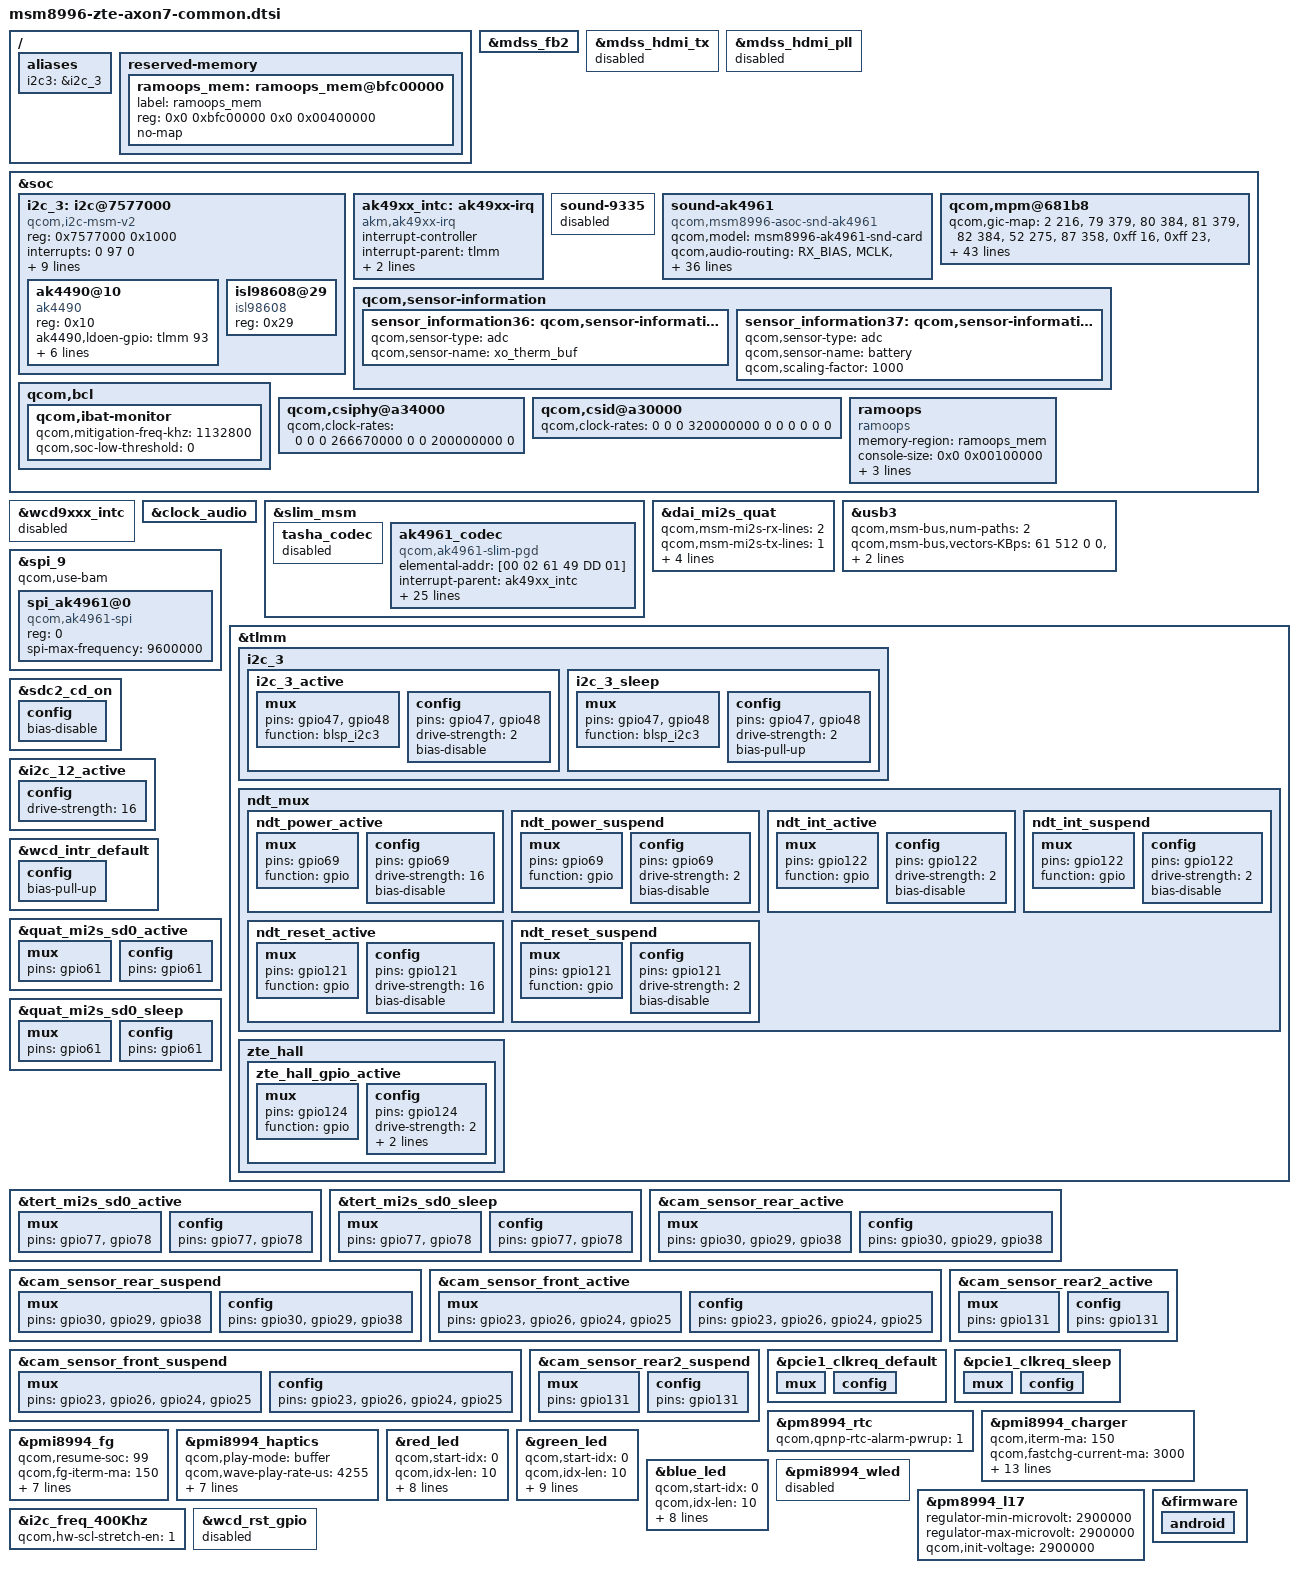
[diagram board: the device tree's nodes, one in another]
/* Copyright (c) 2015-2016, The Linux Foundation. All rights reserved.
 * Copyright (C) 2016 ZTE Corporation.
 *
 * This program is free software; you can redistribute it and/or modify
 * it under the terms of the GNU General Public License version 2 and
 * only version 2 as published by the Free Software Foundation.
 *
 * This program is distributed in the hope that it will be useful,
 * but WITHOUT ANY WARRANTY; without even the implied warranty of
 * MERCHANTABILITY or FITNESS FOR A PARTICULAR PURPOSE.  See the
 * GNU General Public License for more details.
 */

/*
 * ZTE Axon 7 (ailsa_ii): ZTE's changes to the shared msm8996 SoC and PMIC
 * dtsi files.
 *
 * ZTE's 3.18 kernel edited msm8996.dtsi, msm8996-pinctrl.dtsi,
 * msm-pmi8994.dtsi, msm-pm8994.dtsi, msm8996-regulator.dtsi,
 * msm8996-camera.dtsi, msm8996-blsp.dtsi and msm8996-pm.dtsi directly.
 * Here those changes are applied as overrides, so the shared 4.4 files stay
 * untouched. Each section names the file it overrides. Nodes for parts that
 * have no driver in this tree yet (AK4961 codec, AK4490 DAC, AK8157,
 * ISL98608) are kept so the board description is complete; they do not
 * probe until the drivers are ported.
 */

/* ---- msm8996.dtsi ---- */

/ {
	aliases {
		i2c3 = &i2c_3;
	};

	reserved-memory {
		/*
		 * No HDMI on this board. ZTE shrank this region to 0 bytes;
		 * drop it instead and free the 36 MB.
		 */
		/delete-node/ cont_splash_mem_hdmi@bdd00000;

		/*
		 * Where ZTE's 3.18 kernel (TWRP) and mainline (postmarketOS)
		 * keep ramoops, with their layout: the next boot of any of the
		 * three can read the log (dmesg zones, console, ftrace, pmsg).
		 */
		ramoops_mem: ramoops_mem@bfc00000 {
			label = "ramoops_mem";
			reg = <0x0 0xbfc00000 0x0 0x00400000>;
			no-map;
		};
	};
};

&mdss_fb2 {
	/delete-node/ qcom,cont-splash-memory;
};

&mdss_hdmi_tx {
	status = "disabled";
};

&mdss_hdmi_pll {
	status = "disabled";
};

&soc {
	i2c_3: i2c@7577000 { /* BLSP1 QUP3 */
		compatible = "qcom,i2c-msm-v2";
		#address-cells = <1>;
		#size-cells = <0>;
		reg = <0x7577000 0x1000>;
		reg-names = "qup_phys_addr";
		interrupt-names = "qup_irq";
		interrupts = <0 97 0>;
		dmas = <&dma_blsp1 16 64 0x20000020 0x20>,
			<&dma_blsp1 17 32 0x20000020 0x20>;
		dma-names = "tx", "rx";
		qcom,master-id = <86>;
		qcom,clk-freq-out = <400000>;
		qcom,clk-freq-in = <19200000>;
		clock-names = "iface_clk", "core_clk";
		clocks = <&clock_gcc clk_gcc_blsp1_ahb_clk>,
			<&clock_gcc clk_gcc_blsp1_qup3_i2c_apps_clk>;
		pinctrl-names = "i2c_active", "i2c_sleep";
		pinctrl-0 = <&i2c_3_active>;
		pinctrl-1 = <&i2c_3_sleep>;

		/* AKM AK4490 Hi-Fi DAC (no driver in this tree yet) */
		ak4490@10 {
			compatible = "ak4490";
			reg = <0x10>;
			ak4490,ldoen-gpio = <&tlmm 93 0>;
			ak4490,pdn-gpio = <&pmi8994_gpios 1 0>;
			qcom,isl-sw-pwr-gpio = <&pmi8994_gpios 10 0>;
			ak4490,isl-ldo-pwr-gpio = <&pmi8994_mpps 4 0>;
			ak4490,hifi_sel_gpio = <&pm8994_mpps 2 0>;
			ak4490,hifi_mute_gpio = <&pm8994_mpps 4 0>;
			ak4490,hifi_pop_gpio = <&tlmm 74 0>;
		};

		/* Intersil ISL98608 DAC power supply (no driver yet) */
		isl98608@29 {
			compatible = "isl98608";
			reg = <0x29>;
		};
	};

	/*
	 * The WCD9335 is not fitted: the slimbus codec is an AKM AK4961.
	 * Its interrupt line (gpio 54) goes to the AK49xx irq controller.
	 */
	ak49xx_intc: ak49xx-irq {
		compatible = "akm,ak49xx-irq";
		interrupt-controller;
		#interrupt-cells = <1>;
		interrupt-parent = <&tlmm>;
		qcom,gpio-connect = <&tlmm 54 0>;
		pinctrl-names = "default";
		pinctrl-0 = <&wcd_intr_default>;
	};

	sound-9335 {
		status = "disabled";
	};

	/* AK4961 machine driver (sound/soc/msm/msm8996-ak496x.c) */
	sound-ak4961 {
		compatible = "qcom,msm8996-asoc-snd-ak4961";
		qcom,model = "msm8996-ak4961-snd-card";
		qcom,audio-routing =
			"RX_BIAS", "MCLK",
			"AK4490_RX_BIAS", "MCLK";
		qcom,rcv-sw-gpio = <&pm8994_gpios 13 0>;
		qcom,ak4961-mclk-clk-freq = <9600000>;
		asoc-platform = <&pcm0>, <&pcm1>, <&pcm2>, <&voip>, <&voice>,
				<&loopback>, <&compress>, <&hostless>,
				<&afe>, <&lsm>, <&routing>, <&cpe>, <&compr>,
				<&pcmnoirq>;
		asoc-platform-names = "msm-pcm-dsp.0", "msm-pcm-dsp.1",
				"msm-pcm-dsp.2", "msm-voip-dsp",
				"msm-pcm-voice", "msm-pcm-loopback",
				"msm-compress-dsp", "msm-pcm-hostless",
				"msm-pcm-afe", "msm-lsm-client",
				"msm-pcm-routing", "msm-cpe-lsm",
				"msm-compr-dsp", "msm-pcm-dsp-noirq";
		asoc-cpu = <&dai_pri_auxpcm>, <&dai_sec_auxpcm>, <&dai_hdmi>,
				<&dai_mi2s>, <&dai_mi2s_quat>,
				<&sb_0_rx>, <&sb_0_tx>, <&sb_1_rx>, <&sb_1_tx>,
				<&sb_2_rx>, <&sb_2_tx>, <&sb_3_rx>, <&sb_3_tx>,
				<&sb_4_rx>, <&sb_4_tx>, <&sb_5_tx>,
				<&afe_pcm_rx>, <&afe_pcm_tx>,
				<&afe_proxy_rx>, <&afe_proxy_tx>,
				<&incall_record_rx>, <&incall_record_tx>,
				<&incall_music_rx>, <&incall_music2_rx>,
				<&sb_5_rx>;
		asoc-cpu-names = "msm-dai-q6-auxpcm.1", "msm-dai-q6-auxpcm.2",
				"msm-dai-q6-hdmi.8", "msm-dai-q6-mi2s.2",
				"msm-dai-q6-mi2s.3",
				"msm-dai-q6-dev.16384", "msm-dai-q6-dev.16385",
				"msm-dai-q6-dev.16386", "msm-dai-q6-dev.16387",
				"msm-dai-q6-dev.16388", "msm-dai-q6-dev.16389",
				"msm-dai-q6-dev.16390", "msm-dai-q6-dev.16391",
				"msm-dai-q6-dev.16392", "msm-dai-q6-dev.16393",
				"msm-dai-q6-dev.16395", "msm-dai-q6-dev.224",
				"msm-dai-q6-dev.225", "msm-dai-q6-dev.241",
				"msm-dai-q6-dev.240", "msm-dai-q6-dev.32771",
				"msm-dai-q6-dev.32772", "msm-dai-q6-dev.32773",
				"msm-dai-q6-dev.32770", "msm-dai-q6-dev.16394";
		asoc-codec = <&stub_codec>;
		asoc-codec-names = "msm-stub-codec.1";
	};

	/* MPM wakeup map: ZTE adds blsp2_qup_irq(4) (gic 137) */
	qcom,mpm@681b8 {
		qcom,gic-map = <2 216>, /* tsens_upper_lower_int */
				<79 379>,   /* qusb2phy_dmse_hv_prim */
				<80 384>,   /* qusb2phy_dmse_hv_sec */
				<81 379>,   /* qusb2phy_dpse_hv_prim */
				<82 384>,   /* qusb2phy_dpse_hv_sec */
				<52 275>,   /* qmp_usb3_lfps_rxterm_irq */
				<87 358>,   /* ee0_krait_hlos_spmi_periph_irq */
				<0xff 16>,  /* APCj_qgicdrCpu0HwFaultIrptReq */
				<0xff 23>,  /* APCj_qgicdrCpu0PerfMonIrptReq */
				<0xff 27>,  /* APCj_qgicdrCpu0QTmrVirtIrptReq */
				<0xff 32>,  /* APCj_qgicdrL2PerfMonIrptReq */
				<0xff 33>,  /* APCC_qgicL2PerfMonIrptReq */
				<0xff 34>,  /* APCC_qgicL2ErrorIrptReq */
				<0xff 35>,  /* WDT_barkInt */
				<0xff 40>,  /* qtimer_phy_irq */
				<0xff 41>,  /* APCj_qgicdrL2HwFaultNonFatalIrptReq */
				<0xff 42>,  /* APCj_qgicdrL2HwFaultFatalIrptReq */
				<0xff 49>,  /* L3UX_qgicL3ErrorIrptReq */
				<0xff 54>,  /* M4M_sysErrorInterrupt */
				<0xff 55>,  /* M4M_sysDlmInterrupt */
				<0xff 57>,  /* mss_to_apps_irq(0) */
				<0xff 58>,  /* mss_to_apps_irq(1) */
				<0xff 59>,  /* mss_to_apps_irq(2) */
				<0xff 60>,  /* mss_to_apps_irq(3) */
				<0xff 61>,  /* mss_a2_bam_irq */
				<0xff 62>,  /* QTMR_qgicFrm0VirtIrq */
				<0xff 63>,  /* QTMR_qgicFrm1PhysIrq */
				<0xff 64>,  /* QTMR_qgicFrm2PhysIrq */
				<0xff 65>,  /* QTMR_qgicFrm3PhysIrq */
				<0xff 66>,  /* QTMR_qgicFrm4PhysIrq */
				<0xff 67>,  /* QTMR_qgicFrm5PhysIrq */
				<0xff 68>,  /* QTMR_qgicFrm6PhysIrq */
				<0xff 69>,  /* QTMR_qgicFrm7PhysIrq */
				<0xff 70>,  /* iommu_pmon_nonsecure_irq */
				<0xff 74>,  /* osmmu_CIrpt[1] */
				<0xff 75>,  /* osmmu_CIrpt[0] */
				<0xff 77>,  /* osmmu_CIrpt[0] */
				<0xff 78>,  /* osmmu_CIrpt[0] */
				<0xff 79>,  /* osmmu_CIrpt[0] */
				<0xff 80>,  /* CPR3_irq */
				<0xff 94>,  /* osmmu_CIrpt[0] */
				<0xff 97>,  /* iommu_nonsecure_irq */
				<0xff 99>,  /* msm_iommu_pmon_nonsecure_irq */
				<0xff 101>, /* camss_jpeg_mmu_cirpt */
				<0xff 102>, /* osmmu_CIrpt[1] */
				<0xff 105>, /* iommu_pmon_nonsecure_irq */
				<0xff 108>, /* osmmu_PMIrpt */
				<0xff 109>, /* ocmem_dm_nonsec_irq */
				<0xff 110>, /* csiphy_0_irq */
				<0xff 111>, /* csiphy_1_irq */
				<0xff 112>, /* csiphy_2_irq */
				<0xff 115>, /* mdss_irq */
				<0xff 126>, /* bam_irq[0] */
				<0xff 127>, /* blsp1_qup_irq(0) */
				<0xff 129>, /* blsp2_qup_irq(3) */
				<0xff 132>, /* blsp1_qup_irq(5) */
				<0xff 133>, /* blsp2_qup_irq(0) */
				<0xff 134>, /* blsp2_qup_irq(1) */
				<0xff 135>, /* blsp2_qup_irq(3) */
				<0xff 137>, /* ZTE: blsp2_qup_irq(4) */
				<0xff 138>, /* blsp2_qup_irq(5) */
				<0xff 140>, /* blsp1_uart_irq(1) */
				<0xff 146>, /* blsp2_uart_irq(1) */
				<0xff 155>, /* sdcc_irq[0] */
				<0xff 157>, /* sdc2_irq[0] */
				<0xff 163>, /* usb30_ee1_irq */
				<0xff 164>, /* usb30_bam_irq(0) */
				<0xff 165>, /* usb30_hs_phy_irq */
				<0xff 166>, /* sdc1_pwr_cmd_irq */
				<0xff 170>, /* sdcc_pwr_cmd_irq */
				<0xff 171>, /* usb20_hs_phy_irq */
				<0xff 172>, /* usb20_power_event_irq */
				<0xff 173>, /* sdc1_irq[0] */
				<0xff 174>, /* o_wcss_apss_smd_med */
				<0xff 175>, /* o_wcss_apss_smd_low */
				<0xff 176>, /* o_wcss_apss_smsm_irq */
				<0xff 177>, /* o_wcss_apss_wlan_data_xfer_done */
				<0xff 178>, /* o_wcss_apss_wlan_rx_data_avail */
				<0xff 179>, /* o_wcss_apss_asic_intr */
				<0xff 180>, /* pcie20_2_int_pls_err */
				<0xff 181>, /* wcnss watchdog */
				<0xff 188>, /* lpass_irq_out_apcs(0) */
				<0xff 189>, /* lpass_irq_out_apcs(1) */
				<0xff 190>, /* lpass_irq_out_apcs(2) */
				<0xff 191>, /* lpass_irq_out_apcs(3) */
				<0xff 192>, /* lpass_irq_out_apcs(4) */
				<0xff 193>, /* lpass_irq_out_apcs(5) */
				<0xff 194>, /* lpass_irq_out_apcs(6) */
				<0xff 195>, /* lpass_irq_out_apcs(7) */
				<0xff 196>, /* lpass_irq_out_apcs(8) */
				<0xff 197>, /* lpass_irq_out_apcs(9) */
				<0xff 198>, /* coresight-tmc-etr interrupt */
				<0xff 200>, /* rpm_ipc(4) */
				<0xff 201>, /* rpm_ipc(5) */
				<0xff 202>, /* rpm_ipc(6) */
				<0xff 203>, /* rpm_ipc(7) */
				<0xff 204>, /* rpm_ipc(24) */
				<0xff 205>, /* rpm_ipc(25) */
				<0xff 206>, /* rpm_ipc(26) */
				<0xff 207>, /* rpm_ipc(27) */
				<0xff 208>,
				<0xff 210>,
				<0xff 211>, /* usb_dwc3_otg */
				<0xff 212>, /* usb30_power_event_irq */
				<0xff 215>, /* o_bimc_intr(0) */
				<0xff 224>, /* spdm_realtime_irq[1] */
				<0xff 238>, /* crypto_bam_irq[0] */
				<0xff 240>, /* summary_irq_kpss */
				<0xff 253>, /* sdc2_pwr_cmd_irq */
				<0xff 258>, /* lpass_irq_out_apcs[21] */
				<0xff 268>, /* bam_irq[1] */
				<0xff 270>, /* bam_irq[0] */
				<0xff 271>, /* bam_irq[0] */
				<0xff 276>, /* wlan_pci */
				<0xff 283>, /* pcie20_0_int_pls_err */
				<0xff 284>, /* pcie20_0_int_aer_legacy */
				<0xff 286>, /* pcie20_0_int_pls_link_down */
				<0xff 290>, /* ufs_ice_nonsec_level_irq */
				<0xff 293>, /* pcie20_2_int_pls_link_down */
				<0xff 295>, /* camss_cpp_mmu_cirpt[0] */
				<0xff 296>, /* camss_cpp_mmu_pmirpt */
				<0xff 297>, /* ufs_intrq */
				<0xff 298>, /* camss_cpp_mmu_cirpt */
				<0xff 302>, /* qdss_etrbytecnt_irq */
				<0xff 310>, /* pcie20_1_int_pls_err */
				<0xff 311>, /* pcie20_1_int_aer_legacy */
				<0xff 313>, /* pcie20_1_int_pls_link_down */
				<0xff 318>, /* venus0_mmu_pmirpt */
				<0xff 319>, /* venus0_irq */
				<0xff 325>, /* camss_irq18 */
				<0xff 326>, /* camss_irq0 */
				<0xff 327>, /* camss_irq1 */
				<0xff 328>, /* camss_irq2 */
				<0xff 329>, /* camss_irq3 */
				<0xff 330>, /* camss_irq4 */
				<0xff 331>, /* camss_irq5 */
				<0xff 332>, /* sps */
				<0xff 341>, /* camss_irq6 */
				<0xff 346>, /* camss_irq8 */
				<0xff 347>, /* camss_irq9 */
				<0xff 352>, /* mdss_mmu_cirpt[0] */
				<0xff 353>, /* mdss_mmu_cirpt[1] */
				<0xff 361>, /* ogpu_mmu_cirpt[0] */
				<0xff 362>, /* ogpu_mmu_cirpt[1] */
				<0xff 365>, /* ipa_irq[0] */
				<0xff 366>, /* ogpu_mmu_pmirpt */
				<0xff 367>, /* venus0_mmu_cirpt[0] */
				<0xff 368>, /* venus0_mmu_cirpt[1] */
				<0xff 369>, /* venus0_mmu_cirpt[2] */
				<0xff 370>, /* venus0_mmu_cirpt[3] */
				<0xff 375>, /* camss_vfe_mmu_cirpt[0] */
				<0xff 376>, /* camss_vfe_mmu_cirpt[1] */
				<0xff 380>, /* mdss_dma_mmu_cirpt[0] */
				<0xff 381>, /* mdss_dma_mmu_cirpt[1] */
				<0xff 385>, /* mdss_dma_mmu_pmirpt */
				<0xff 387>, /* osmmu_CIrpt[0] */
				<0xff 394>, /* osmmu_PMIrpt */
				<0xff 403>, /* osmmu_PMIrpt */
				<0xff 405>, /* osmmu_CIrpt[0] */
				<0xff 413>, /* osmmu_PMIrpt */
				<0xff 422>, /* ssc_irq_out_apcs[5] */
				<0xff 424>, /* ipa_irq[2] */
				<0xff 425>, /* lpass_irq_out_apcs[22] */
				<0xff 426>, /* lpass_irq_out_apcs[23] */
				<0xff 427>, /* lpass_irq_out_apcs[24] */
				<0xff 428>, /* lpass_irq_out_apcs[25] */
				<0xff 429>, /* lpass_irq_out_apcs[26] */
				<0xff 430>, /* lpass_irq_out_apcs[27] */
				<0xff 431>, /* lpass_irq_out_apcs[28] */
				<0xff 432>, /* lpass_irq_out_apcs[29] */
				<0xff 436>, /* lpass_irq_out_apcs[37] */
				<0xff 437>, /* pcie20_0_int_msi_dev0 */
				<0xff 445>, /* pcie20_1_int_msi_dev0 */
				<0xff 453>, /* pcie20_2_int_msi_dev0 */
				<0xff 461>, /* o_vmem_nonsec_irq */
				<0xff 462>, /* tsens1_tsens_critical_int */
				<0xff 464>, /* ipa_bam_irq[0] */
				<0xff 465>, /* ipa_bam_irq[2] */
				<0xff 477>, /* tsens0_tsens_critical_int */
				<0xff 480>, /* q6_wdog_expired_irq */
				<0xff 481>, /* mss_ipc_out_irq(4) */
				<0xff 483>, /* mss_ipc_out_irq(6) */
				<0xff 484>, /* mss_ipc_out_irq(7) */
				<0xff 487>, /* mss_ipc_out_irq(30) */
				<0xff 490>, /* tsens0_tsens_upper_lower_int */
				<0xff 493>;
	};

	qcom,sensor-information {
		sensor_information36: qcom,sensor-information-36 {
			qcom,sensor-type = "adc";
			qcom,sensor-name = "xo_therm_buf";
		};

		sensor_information37: qcom,sensor-information-37 {
			qcom,sensor-type = "adc";
			qcom,sensor-name = "battery";
			qcom,scaling-factor = <1000>;
		};
	};

	qcom,bcl {
		/delete-property/ qcom,bcl-hotplug-list;
		/delete-property/ qcom,bcl-soc-hotplug-list;

		qcom,ibat-monitor {
			qcom,mitigation-freq-khz = <1132800>;
			qcom,soc-low-threshold = <0>;
		};
	};
};

&wcd9xxx_intc {
	status = "disabled";
};

&clock_audio {
	/* the speaker I2S clock pin is not used on this board */
	/delete-property/ pinctrl-names;
	/delete-property/ pinctrl-0;
	/delete-property/ pinctrl-1;
};

&slim_msm {
	tasha_codec {
		status = "disabled";
	};

	/* AKM AK4961 audio codec (drivers/mfd/ak49xx-*, sound/soc/codecs/ak4961.c) */
	ak4961_codec {
		compatible = "qcom,ak4961-slim-pgd";
		elemental-addr = [00 02 61 49 DD 01];

		interrupt-parent = <&ak49xx_intc>;
		interrupts = <0 1 2 3 4 5 6 7 8 9 10 11 12 13 14 15 16
			      17 18 19 20 21 22 23 24 25 26 27 28 29
			      30 31>;

		akm,cdc-reset-gpio = <&tlmm 64 0>;
		akm,cdc-ldo-gpio = <&tlmm 63 0>;
		akm,cdc-cif1-gpio = <&tlmm 62 0>;
		nxp,smartpa-rst1-gpio = <&pmi8994_gpios 2 0>;
		nxp,smartpa-rst2-gpio = <&pmi8994_gpios 3 0>;

		clock-names = "cdc_clk";
		clocks = <&clock_audio clk_audio_pmi_clk>;

		cdc-vdd-tx-h-supply = <&pm8994_s4>;
		akm,cdc-vdd-tx-h-voltage = <1800000 1800000>;
		akm,cdc-vdd-tx-h-current = <20000>;

		cdc-vdd-rx-h-supply = <&pm8994_s4>;
		akm,cdc-vdd-rx-h-voltage = <1800000 1800000>;
		akm,cdc-vdd-rx-h-current = <20000>;

		cdc-vdd-px-supply = <&pm8994_s4>;
		akm,cdc-vdd-px-voltage = <1800000 1800000>;
		akm,cdc-vdd-px-current = <45000>;

		akm,cdc-static-supplies = "cdc-vdd-tx-h",
					   "cdc-vdd-rx-h",
					   "cdc-vdd-px";

		akm,cdc-micbias-mpwr1-mv = <0>;
		akm,cdc-micbias-mpwr2-mv = <2800>;

		akm,cdc-mclk-clk-rate = <9600000>;
		akm,cdc-slim-ifd = "ak4961-slim-ifd";
		akm,cdc-slim-ifd-elemental-addr = [00 00 61 49 DD 01];
	};
};

&dai_mi2s_quat {
	/* AK4490 DAC path */
	qcom,msm-mi2s-rx-lines = <2>;
	qcom,msm-mi2s-tx-lines = <1>;
	pinctrl-names = "default", "sleep";
	pinctrl-0 = <&quat_mi2s_active &quat_mi2s_sd0_active>;
	pinctrl-1 = <&quat_mi2s_sleep &quat_mi2s_sd0_sleep>;
};

&usb3 {
	/*
	 * ZTE votes a second bus path (master 87) next to the USB3 master.
	 * 3.18 had three use cases, 4.4 has two (off, on).
	 */
	qcom,msm-bus,num-paths = <2>;
	qcom,msm-bus,vectors-KBps =
		<61 512 0 0>, <87 512 0 0>,
		<61 512 240000 800000>, <87 512 240000 800000>;
};

/* ---- msm8996-blsp.dtsi ---- */

&spi_9 { /* BLSP2 QUP3 */
	qcom,use-bam;
	status = "okay";

	/* AK4961 control port (no driver yet) */
	spi_ak4961@0 {
		compatible = "qcom,ak4961-spi";
		reg = <0>;
		spi-max-frequency = <9600000>;
	};
};

/* ---- msm8996-pinctrl.dtsi ---- */

&tlmm {
	i2c_3 { /* BLSP1 QUP3 */
		i2c_3_active: i2c_3_active {
			mux {
				pins = "gpio47", "gpio48";
				function = "blsp_i2c3";
			};

			config {
				pins = "gpio47", "gpio48";
				drive-strength = <2>;
				bias-disable;
			};
		};

		i2c_3_sleep: i2c_3_sleep {
			mux {
				pins = "gpio47", "gpio48";
				function = "blsp_i2c3";
			};

			config {
				pins = "gpio47", "gpio48";
				drive-strength = <2>;
				bias-pull-up;
			};
		};
	};

	/* NDT force sensor on the touch bus */
	ndt_mux {
		ndt_power_active: ndt_power_active {
			mux {
				pins = "gpio69";
				function = "gpio";
			};

			config {
				pins = "gpio69";
				drive-strength = <16>;
				bias-disable;
			};
		};

		ndt_power_suspend: ndt_power_suspend {
			mux {
				pins = "gpio69";
				function = "gpio";
			};

			config {
				pins = "gpio69";
				drive-strength = <2>;
				bias-disable;
			};
		};

		ndt_int_active: ndt_int_active {
			mux {
				pins = "gpio122";
				function = "gpio";
			};

			config {
				pins = "gpio122";
				drive-strength = <2>;
				bias-disable;
			};
		};

		ndt_int_suspend: ndt_int_suspend {
			mux {
				pins = "gpio122";
				function = "gpio";
			};

			config {
				pins = "gpio122";
				drive-strength = <2>;
				bias-disable;
			};
		};

		ndt_reset_active: ndt_reset_active {
			mux {
				pins = "gpio121";
				function = "gpio";
			};

			config {
				pins = "gpio121";
				drive-strength = <16>;
				bias-disable;
			};
		};

		ndt_reset_suspend: ndt_reset_suspend {
			mux {
				pins = "gpio121";
				function = "gpio";
			};

			config {
				pins = "gpio121";
				drive-strength = <2>;
				bias-disable;
			};
		};
	};

	/* Hall sensor (flip cover), gpio 124 */
	zte_hall {
		zte_hall_gpio_active: zte_hall_gpio_active {
			mux {
				pins = "gpio124";
				function = "gpio";
			};

			config {
				pins = "gpio124";
				drive-strength = <2>;
				bias-disable;
				input-enable;
			};
		};
	};
};

/* microSD card detect: no pull (ZTE board has an external pull) */
&sdc2_cd_on {
	config {
		/delete-property/ bias-pull-up;
		bias-disable;
	};
};

&i2c_12_active {
	config {
		drive-strength = <16>;
	};
};

/* AK4961 interrupt is active low */
&wcd_intr_default {
	config {
		/delete-property/ bias-pull-down;
		bias-pull-up;
	};
};

/* quaternary MI2S (AK4490): data on gpio 61 */
&quat_mi2s_sd0_active {
	mux {
		pins = "gpio61";
	};

	config {
		pins = "gpio61";
	};
};

&quat_mi2s_sd0_sleep {
	mux {
		pins = "gpio61";
	};

	config {
		pins = "gpio61";
	};
};

&tert_mi2s_sd0_active {
	mux {
		pins = "gpio77", "gpio78";
	};

	config {
		pins = "gpio77", "gpio78";
	};
};

&tert_mi2s_sd0_sleep {
	mux {
		pins = "gpio77", "gpio78";
	};

	config {
		pins = "gpio77", "gpio78";
	};
};

/* camera: rear also drives gpio 38, front also 24/25 (DVDD/IOVDD enables) */
&cam_sensor_rear_active {
	mux {
		pins = "gpio30", "gpio29", "gpio38";
	};

	config {
		pins = "gpio30", "gpio29", "gpio38";
	};
};

&cam_sensor_rear_suspend {
	mux {
		pins = "gpio30", "gpio29", "gpio38";
	};

	config {
		pins = "gpio30", "gpio29", "gpio38";
	};
};

&cam_sensor_front_active {
	mux {
		pins = "gpio23", "gpio26", "gpio24", "gpio25";
	};

	config {
		pins = "gpio23", "gpio26", "gpio24", "gpio25";
	};
};

&cam_sensor_front_suspend {
	mux {
		pins = "gpio23", "gpio26", "gpio24", "gpio25";
	};

	config {
		pins = "gpio23", "gpio26", "gpio24", "gpio25";
	};
};

/*
 * gpio 62/63 belong to the AK4961 (cif1/ldo enable). ZTE parked the
 * rear2 camera pin states on the unused gpio 131 (PCIe1 CLKREQ, whose pin
 * states lose their pins below) so they do not claim those pins.
 */
&cam_sensor_rear2_active {
	mux {
		pins = "gpio131";
	};

	config {
		pins = "gpio131";
	};
};

&cam_sensor_rear2_suspend {
	mux {
		pins = "gpio131";
	};

	config {
		pins = "gpio131";
	};
};

&pcie1_clkreq_default {
	mux {
		/delete-property/ pins;
	};

	config {
		/delete-property/ pins;
	};
};

&pcie1_clkreq_sleep {
	mux {
		/delete-property/ pins;
	};

	config {
		/delete-property/ pins;
	};
};

/* ---- msm-pm8994.dtsi ---- */

&pm8994_rtc {
	/* allow the RTC alarm to power the phone on (power-off alarm) */
	qcom,qpnp-rtc-alarm-pwrup = <1>;
};

/* ---- msm-pmi8994.dtsi ---- */

&pmi8994_charger {
	qcom,iterm-ma = <150>;
	qcom,fastchg-current-ma = <3000>;
	qcom,float-voltage-mv = <4400>;
	qcom,fastchg-current-comp = <1200>;	/* index 2, as ZTE 3.18 wrote with its 900 (PMI8994 table) */
	qcom,float-voltage-comp = <10>;
	qcom,resume-delta-mv = <100>;
	qcom,parallel-usb-min-current-ma = <1000>;
	qcom,charge-unknown-battery;
	qcom,bmd-pin-src = "bpd_thm";
	qcom,charging-timeout-mins = <768>;
	qcom,precharging-timeout-mins = <24>;
	/* ZTE smbcharger extensions; ignored by the 4.4 driver */
	qcom,vchg-adc-channel-id = <3>;
	qcom,vchg_sns-vadc = <&pmi8994_vadc>;
	qcom,apsd_rerun_config_enable;
	qcom,design_capacity = <3200>;
};

&pmi8994_fg {
	qcom,resume-soc = <99>;
	qcom,fg-iterm-ma = <150>;
	qcom,thermal-coefficients = [EC 85 75 4A FC 35];
	qcom,fg-chg-iterm-ma = <150>;
	qcom,fg-cc-cv-threshold-mv = <4390>;
	qcom,fg-cutoff-voltage-mv = <3400>;
	qcom,hold-soc-while-full;
	qcom,fg-delta-soc = <2>;
	qcom,vbat-estimate-diff-mv = <150>;
};

/*
 * LRA haptics. ZTE's 3.18 values, written for the 4.4 qpnp-haptics
 * (leds-qpnp-haptics) binding.
 */
&pmi8994_haptics {
	qcom,play-mode = "buffer";
	qcom,wave-play-rate-us = <4255>;
	qcom,wave-shape = "sine";
	qcom,vmax-mv = <2668>;
	qcom,wave-samples = <0x33 0x33 0x33 0x33 0x33 0x33 0x33 0x33>;
	qcom,lra-high-z = "opt1";
	qcom,lra-auto-res-mode = "qwd";
	qcom,lra-res-cal-period = <4>;
};

&red_led {
	qcom,start-idx = <0>;
	qcom,idx-len = <10>;
	qcom,ramp-step-ms = <10>;
	qcom,lut-flags = <31>;
	qcom,pause-lo = <2200>;
	qcom,pause-hi = <1300>;
	qcom,duty-pcts = [00 05 0A 0F 14 19 1E 23 28 2D];
	qcom,max-current = <6>;
	qcom,use-blink;
};

&green_led {
	qcom,start-idx = <0>;
	qcom,idx-len = <10>;
	qcom,ramp-step-ms = <10>;
	qcom,lut-flags = <31>;
	qcom,pause-lo = <2200>;
	qcom,pause-hi = <1300>;
	qcom,duty-pcts = [00 05 0A 0F 14 19 1E 23 28 2D];
	qcom,max-current = <6>;
	linux,default-trigger = "none";
	qcom,use-blink;
};

&blue_led {
	qcom,start-idx = <0>;
	qcom,idx-len = <10>;
	qcom,ramp-step-ms = <10>;
	qcom,lut-flags = <31>;
	qcom,pause-lo = <2200>;
	qcom,pause-hi = <1300>;
	qcom,duty-pcts = [00 05 0A 0F 14 19 1E 23 28 2D];
	qcom,max-current = <6>;
	linux,default-trigger = "none";
};

/* AMOLED panel: backlight is set over DCS, the WLED is unused */
&pmi8994_wled {
	status = "disabled";
};

/* ZTE removed the flash "switch" LED (no camera switch on this board) */
/delete-node/ &pmi8994_switch;

/* ---- msm8996-regulator.dtsi ---- */

&pm8994_l17 { /* rear camera AVDD */
	regulator-min-microvolt = <2900000>;
	regulator-max-microvolt = <2900000>;
	qcom,init-voltage = <2900000>;
};

/* ---- msm8996-camera.dtsi ---- */

&soc {
	qcom,csiphy@a34000 {
		qcom,clock-rates = <0 0 0 266670000 0 0 200000000 0>;
	};

	qcom,csid@a30000 {
		qcom,clock-rates = <0 0 0 320000000 0 0 0 0 0 0>;
	};
};

&i2c_freq_400Khz {
	qcom,hw-scl-stretch-en = <1>;
};

/* ---- LineageOS ---- */

&soc {
	/* pstore: last kernel log in /sys/fs/pstore after a reboot */
	ramoops {
		compatible = "ramoops";
		status = "ok";
		memory-region = <&ramoops_mem>;

		console-size = <0x0 0x00100000>;
		pmsg-size = <0x0 0x00100000>;
		record-size = <0x0 0x00008000>;
		ftrace-size = <0x0 0x00100000>;
	};
};

&firmware {
	android {
		/* system and vendor are mounted from the ramdisk fstab */
		/delete-node/ fstab;
		/delete-node/ vbmeta;
	};
};

/* gpio 64 is the AK4961 reset (akm,cdc-reset-gpio); no WCD9335 reset pin */
&wcd_rst_gpio {
	status = "disabled";
};
